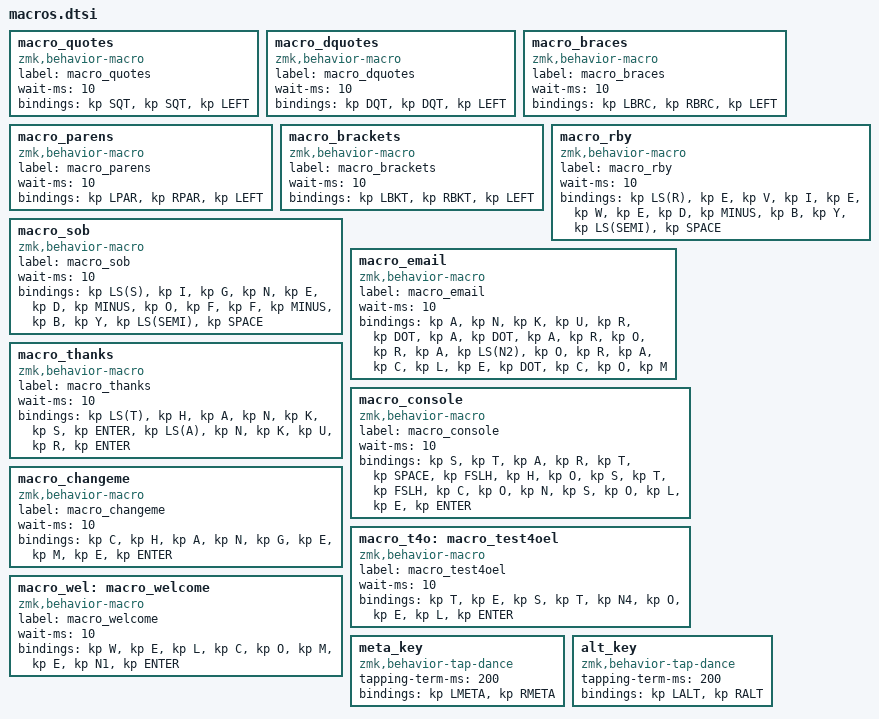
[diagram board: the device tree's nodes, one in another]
  macro_quotes: macro_quotes {
    compatible = "zmk,behavior-macro";
    label = "macro_quotes";
    wait-ms = <10>;
    #binding-cells = <0>;
    bindings = <&kp SQT>, <&kp SQT>, <&kp LEFT>;
  };
  macro_dquotes: macro_dquotes {
    compatible = "zmk,behavior-macro";
    label = "macro_dquotes";
    wait-ms = <10>;
    #binding-cells = <0>;
    bindings = <&kp DQT>, <&kp DQT>, <&kp LEFT>;
  };
  macro_braces: macro_braces {
    compatible = "zmk,behavior-macro";
    label = "macro_braces";
    wait-ms = <10>;
    #binding-cells = <0>;
    bindings = <&kp LBRC>, <&kp RBRC>, <&kp LEFT>;
  };
  macro_parens: macro_parens {
    compatible = "zmk,behavior-macro";
    label = "macro_parens";
    wait-ms = <10>;
    #binding-cells = <0>;
    bindings = <&kp LPAR>, <&kp RPAR>, <&kp LEFT>;
  };
  macro_brackets: macro_brackets {
    compatible = "zmk,behavior-macro";
    label = "macro_brackets";
    wait-ms = <10>;
    #binding-cells = <0>;
    bindings = <&kp LBKT>, <&kp RBKT>, <&kp LEFT>;
  };
  macro_rby: macro_rby {
    compatible = "zmk,behavior-macro";
    label = "macro_rby";
    wait-ms = <10>;
    #binding-cells = <0>;
    bindings = <&kp LS(R)>, <&kp E>, <&kp V>, <&kp I>, <&kp E>, <&kp W>, <&kp E>, <&kp D>, <&kp MINUS>, <&kp B>, <&kp Y>, <&kp LS(SEMI)>, <&kp SPACE>;
  };
  macro_sob: macro_sob {
    compatible = "zmk,behavior-macro";
    label = "macro_sob";
    wait-ms = <10>;
    #binding-cells = <0>;
    bindings = <&kp LS(S)>, <&kp I>, <&kp G>, <&kp N>, <&kp E>, <&kp D>, <&kp MINUS>, <&kp O>, <&kp F>, <&kp F>, <&kp MINUS>, <&kp B>, <&kp Y>, <&kp LS(SEMI)>, <&kp SPACE>;
  };
  macro_email: macro_email {
    compatible = "zmk,behavior-macro";
    label = "macro_email";
    wait-ms = <10>;
    #binding-cells = <0>;
    bindings = <&kp A>, <&kp N>, <&kp K>, <&kp U>, <&kp R>, <&kp DOT>, <&kp A>, <&kp DOT>, <&kp A>, <&kp R>, <&kp O>, <&kp R>, <&kp A>, <&kp LS(N2)>, <&kp O>, <&kp R>, <&kp A>, <&kp C>, <&kp L>, <&kp E>, <&kp DOT>, <&kp C>, <&kp O>, <&kp M>;
  };

  macro_thanks: macro_thanks {
    compatible = "zmk,behavior-macro";
    label = "macro_thanks";
    wait-ms = <10>;
    #binding-cells = <0>;
    bindings = <&kp LS(T)>, <&kp H>, <&kp A>, <&kp N>, <&kp K>, <&kp S>, <&kp ENTER>, <&kp LS(A)>, <&kp N>, <&kp K>, <&kp U>, <&kp R>, <&kp ENTER>;
  };

  macro_console: macro_console {
    compatible = "zmk,behavior-macro";
    label = "macro_console";
    wait-ms = <10>;
    #binding-cells = <0>;
    bindings = <&kp S>, <&kp T>, <&kp A>, <&kp R>, <&kp T>, <&kp SPACE>, <&kp FSLH>, <&kp H>, <&kp O>, <&kp S>, <&kp T>, <&kp FSLH>, <&kp C>, <&kp O>, <&kp N>, <&kp S>, <&kp O>, <&kp L>, <&kp E>, <&kp ENTER>;
  };

  macro_changeme: macro_changeme {
    compatible = "zmk,behavior-macro";
    label = "macro_changeme";
    wait-ms = <10>;
    #binding-cells = <0>;
    bindings = <&kp C>, <&kp H>, <&kp A>, <&kp N>, <&kp G>, <&kp E>, <&kp M>, <&kp E>, <&kp ENTER>;
  };

  macro_t4o: macro_test4oel {
    compatible = "zmk,behavior-macro";
    label = "macro_test4oel";
    wait-ms = <10>;
    #binding-cells = <0>;
    bindings = <&kp T>, <&kp E>, <&kp S>, <&kp T>, <&kp N4>, <&kp O>, <&kp E>, <&kp L>, <&kp ENTER>;

  };

  macro_wel: macro_welcome {
    compatible = "zmk,behavior-macro";
    label = "macro_welcome";
    wait-ms = <10>;
    #binding-cells = <0>;
    bindings = <&kp W>, <&kp E>, <&kp L>, <&kp C>, <&kp O>, <&kp M>, <&kp E>, <&kp N1>, <&kp ENTER>;
  };

  meta_key: meta_key {
    compatible = "zmk,behavior-tap-dance";
    tapping-term-ms = <200>;
    #binding-cells = <0>;
    bindings = <&kp LMETA>, <&kp RMETA>;
  };

  alt_key: alt_key {
    compatible = "zmk,behavior-tap-dance";
    tapping-term-ms = <200>;
    #binding-cells = <0>;
    bindings = <&kp LALT>, <&kp RALT>;
  };
